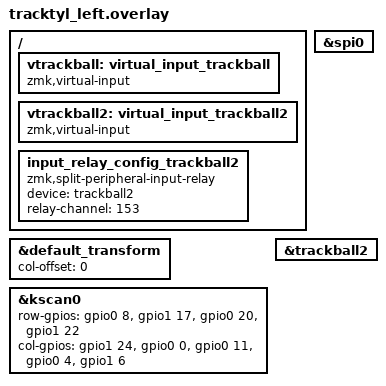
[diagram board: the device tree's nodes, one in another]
#include "tracktyl.dtsi" // Notice that the main dtsi files are included in the overlay.
#include "tracktyl_3610.dtsi"

&default_transform {
    col-offset = <0>;
};

&kscan0 {
       

       row-gpios
            = <&gpio0 8 (GPIO_ACTIVE_HIGH | GPIO_PULL_DOWN)>
            , <&gpio1 17 (GPIO_ACTIVE_HIGH | GPIO_PULL_DOWN)>
            , <&gpio0 20 (GPIO_ACTIVE_HIGH | GPIO_PULL_DOWN)>
            , <&gpio1 22 (GPIO_ACTIVE_HIGH | GPIO_PULL_DOWN)>
            ;

        col-gpios
            = <&gpio1 24 GPIO_ACTIVE_HIGH>
            , <&gpio0 0 GPIO_ACTIVE_HIGH>
            , <&gpio0 11 GPIO_ACTIVE_HIGH>
            , <&gpio0 4 GPIO_ACTIVE_HIGH>
            , <&gpio1 6 GPIO_ACTIVE_HIGH>
            ;
        
};



&spi0 {
    status = "okay";
};

&trackball2 {
    status = "okay";
};

/ {
	vtrackball: virtual_input_trackball {
		compatible = "zmk,virtual-input";
	};
	vtrackball2: virtual_input_trackball2 {
		compatible = "zmk,virtual-input";
	};
	input_relay_config_trackball2 {
		compatible = "zmk,split-peripheral-input-relay";
		device = <&trackball2>;
		relay-channel = <153>;
	};
};
